# STM32F437 register map
File version: 1.3
CPU: CM4 r0p1, little endian, MPU, FPU, 4 interrupt priority bits
Registers are 32-bit, read-write, reset 0x0 unless marked. A register's access mark holds for its fields unless they carry their own. Offsets are from the block's base; [hi:lo] are bit positions; {n}, {i} and the like mark numbered series; 'fields as' and 'values as' point back to an identical list.

## Ethernet_PTP — Ethernet: Precision time protocol
Base 0x40028700
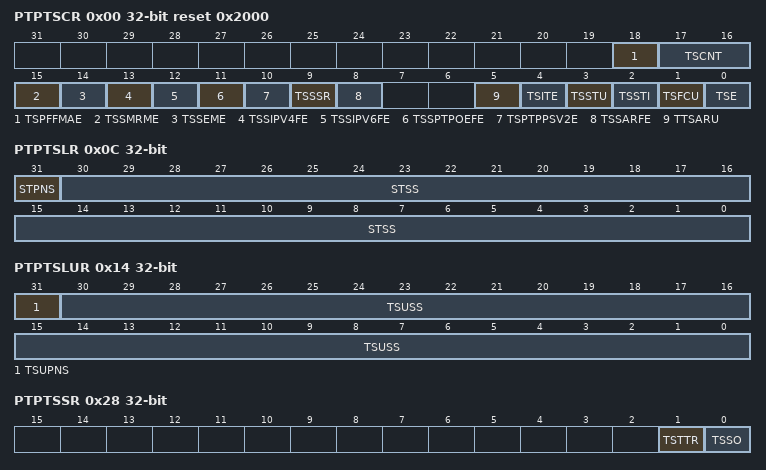
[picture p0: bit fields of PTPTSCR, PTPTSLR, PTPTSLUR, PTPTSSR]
0x00 PTPTSCR reset 0x2000 — Ethernet PTP time stamp control register
  [18] TSPFFMAE, [17:16] TSCNT, [15] TSSMRME, [14] TSSEME, [13] TSSIPV4FE, [12] TSSIPV6FE, [11] TSSPTPOEFE, [10] TSPTPPSV2E, [9] TSSSR, [8] TSSARFE, [5] TTSARU, [4] TSITE, [3] TSSTU, [2] TSSTI, [1] TSFCU, [0] TSE
0x04 PTPSSIR — Ethernet PTP subsecond increment register
  [7:0] STSSI
0x08 PTPTSHR ro — Ethernet PTP time stamp high register
  [31:0] STS
0x0C PTPTSLR ro — Ethernet PTP time stamp low register
  [31] STPNS, [30:0] STSS
0x10 PTPTSHUR — Ethernet PTP time stamp high update register
  [31:0] TSUS
0x14 PTPTSLUR — Ethernet PTP time stamp low update register
  [31] TSUPNS, [30:0] TSUSS
0x18 PTPTSAR — Ethernet PTP time stamp addend register
  [31:0] TSA
0x1C PTPTTHR — Ethernet PTP target time high register
  [31:0] TTSH — 0
0x20 PTPTTLR — Ethernet PTP target time low register
  [31:0] TTSL
0x28 PTPTSSR ro — Ethernet PTP time stamp status register
  [1] TSTTR, [0] TSSO
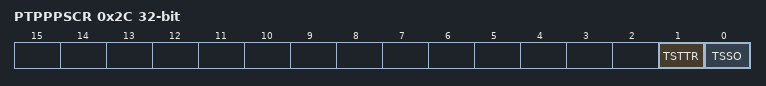
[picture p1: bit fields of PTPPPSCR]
0x2C PTPPPSCR ro — Ethernet PTP PPS control register
  [1] TSTTR, [0] TSSO

## Ethernet_DMA — Ethernet: DMA controller operation
Base 0x40029000
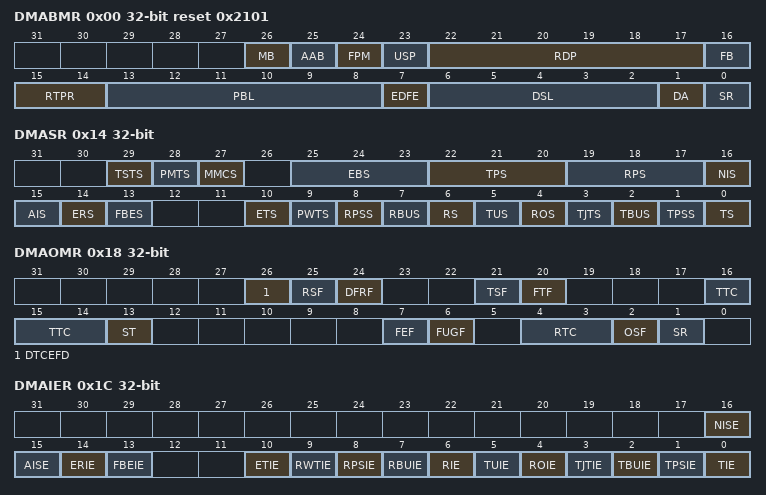
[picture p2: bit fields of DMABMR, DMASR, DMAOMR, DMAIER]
0x00 DMABMR reset 0x2101 — Ethernet DMA bus mode register
  [26] MB, [25] AAB, [24] FPM, [23] USP, [22:17] RDP, [16] FB, [15:14] RTPR, [13:8] PBL, [7] EDFE, [6:2] DSL, [1] DA, [0] SR
0x04 DMATPDR — Ethernet DMA transmit poll demand register
  [31:0] TPD
0x08 DMARPDR — EHERNET DMA receive poll demand register
  [31:0] RPD
0x0C DMARDLAR — Ethernet DMA receive descriptor list address register
  [31:0] SRL
0x10 DMATDLAR — Ethernet DMA transmit descriptor list address register
  [31:0] STL
0x14 DMASR access per field — Ethernet DMA status register
  [29] TSTS ro
  [28] PMTS ro
  [27] MMCS ro
  [25:23] EBS ro
  [22:20] TPS ro
  [19:17] RPS ro
  [16] NIS rw
  [15] AIS rw
  [14] ERS rw
  [13] FBES rw
  [10] ETS rw
  [9] PWTS rw
  [8] RPSS rw
  [7] RBUS rw
  [6] RS rw
  [5] TUS rw
  [4] ROS rw
  [3] TJTS rw
  [2] TBUS rw — TPSS
  [1] TPSS rw
  [0] TS rw
0x18 DMAOMR — Ethernet DMA operation mode register
  [26] DTCEFD, [25] RSF, [24] DFRF, [21] TSF, [20] FTF, [16:14] TTC, [13] ST, [7] FEF, [6] FUGF, [4:3] RTC, [2] OSF, [1] SR
0x1C DMAIER — Ethernet DMA interrupt enable register
  [16] NISE, [15] AISE, [14] ERIE, [13] FBEIE, [10] ETIE, [9] RWTIE, [8] RPSIE, [7] RBUIE, [6] RIE, [5] TUIE, [4] ROIE, [3] TJTIE, [2] TBUIE, [1] TPSIE, [0] TIE
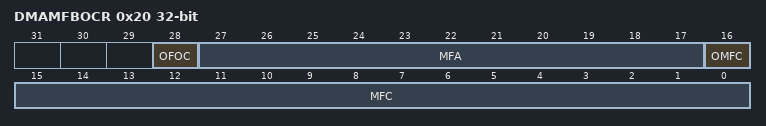
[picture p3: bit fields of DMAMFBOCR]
0x20 DMAMFBOCR — Ethernet DMA missed frame and buffer overflow counter register
  [28] OFOC, [27:17] MFA, [16] OMFC, [15:0] MFC
0x24 DMARSWTR — Ethernet DMA receive status watchdog timer register
  [7:0] RSWTC
0x48 DMACHTDR ro — Ethernet DMA current host transmit descriptor register
  [31:0] HTDAP
0x4C DMACHRDR ro — Ethernet DMA current host receive descriptor register
  [31:0] HRDAP
0x50 DMACHTBAR ro — Ethernet DMA current host transmit buffer address register
  [31:0] HTBAP
0x54 DMACHRBAR ro — Ethernet DMA current host receive buffer address register
  [31:0] HRBAP

## CRC — Cryptographic processor
Base 0x40023000
0x00 DR reset 0xFFFFFFFF — Data register
  [31:0] DR — Data Register
0x04 IDR — Independent Data register
  [7:0] IDR
0x08 CR wo — Control register
  [0] CR — Control regidter

## OTG_FS_HOST — USB on the go full speed
Base 0x50000400
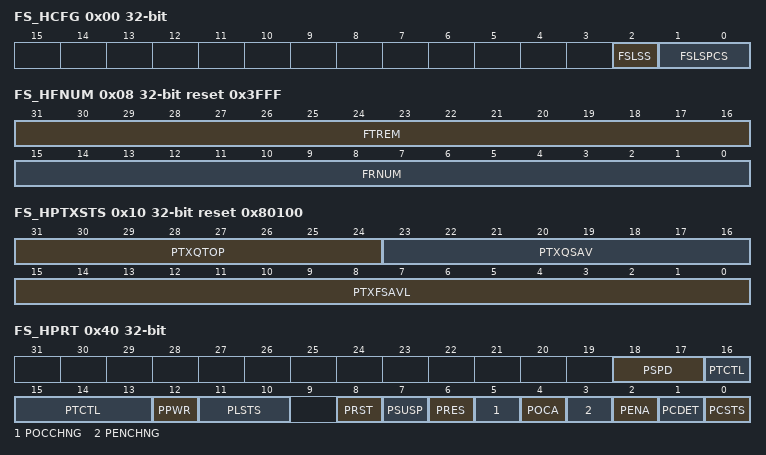
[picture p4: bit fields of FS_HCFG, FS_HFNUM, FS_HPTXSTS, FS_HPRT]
0x00 FS_HCFG access per field — OTG_FS host configuration register (OTG_FS_HCFG)
  [2] FSLSS ro — FS- and LS-only support
  [1:0] FSLSPCS rw — FS/LS PHY clock select
0x04 HFIR reset 0xEA60 — OTG_FS Host frame interval register
  [15:0] FRIVL — Frame interval
0x08 FS_HFNUM ro reset 0x3FFF — OTG_FS host frame number/frame time remaining register (OTG_FS_HFNUM)
  [31:16] FTREM — Frame time remaining
  [15:0] FRNUM — Frame number
0x10 FS_HPTXSTS access per field reset 0x80100 — OTG_FS_Host periodic transmit FIFO/queue status register (OTG_FS_HPTXSTS)
  [31:24] PTXQTOP ro — Top of the periodic transmit request queue
  [23:16] PTXQSAV ro — Periodic transmit request queue space available
  [15:0] PTXFSAVL rw — Periodic transmit data FIFO space available
0x14 HAINT ro — OTG_FS Host all channels interrupt register
  [15:0] HAINT — Channel interrupts
0x18 HAINTMSK — OTG_FS host all channels interrupt mask register
  [15:0] HAINTM — Channel interrupt mask
0x40 FS_HPRT access per field — OTG_FS host port control and status register (OTG_FS_HPRT)
  [18:17] PSPD ro — Port speed
  [16:13] PTCTL rw — Port test control
  [12] PPWR rw — Port power
  [11:10] PLSTS ro — Port line status
  [8] PRST rw — Port reset
  [7] PSUSP rw — Port suspend
  [6] PRES rw — Port resume
  [5] POCCHNG rw — Port overcurrent change
  [4] POCA ro — Port overcurrent active
  [3] PENCHNG rw — Port enable/disable change
  [2] PENA rw — Port enable
  [1] PCDET rw — Port connect detected
  [0] PCSTS ro — Port connect status
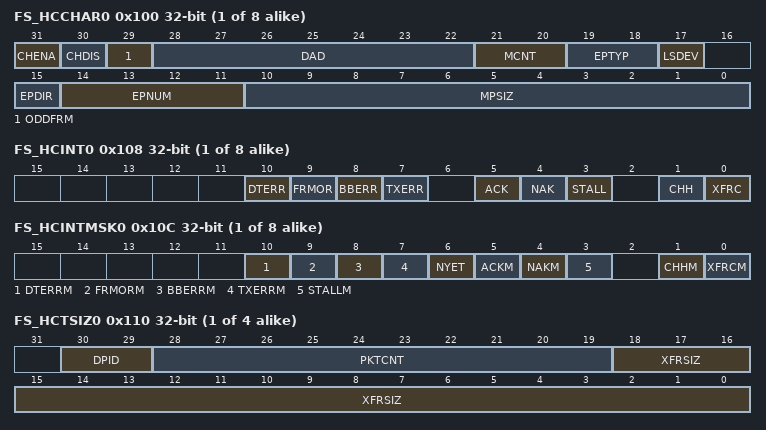
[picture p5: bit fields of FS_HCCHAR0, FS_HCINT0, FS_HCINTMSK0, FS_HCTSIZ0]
{0x100+0x20*i} FS_HCCHAR{i} (i=0..7) — OTG_FS host channel-{i} characteristics register (OTG_FS_HCCHAR{i})
  [31] CHENA — Channel enable
  [30] CHDIS — Channel disable
  [29] ODDFRM — Odd frame
  [28:22] DAD — Device address
  [21:20] MCNT — Multicount
  [19:18] EPTYP — Endpoint type
  [17] LSDEV — Low-speed device
  [15] EPDIR — Endpoint direction
  [14:11] EPNUM — Endpoint number
  [10:0] MPSIZ — Maximum packet size
{0x108+0x20*i} FS_HCINT{i} (i=0..7) — OTG_FS host channel-{i} interrupt register (OTG_FS_HCINT{i})
  [10] DTERR — Data toggle error
  [9] FRMOR — Frame overrun
  [8] BBERR — Babble error
  [7] TXERR — Transaction error
  [5] ACK — ACK response received/transmitted interrupt
  [4] NAK — NAK response received interrupt
  [3] STALL — STALL response received interrupt
  [1] CHH — Channel halted
  [0] XFRC — Transfer completed
{0x10C+0x20*i} FS_HCINTMSK{i} (i=0..7) — OTG_FS host channel-{i} mask register (OTG_FS_HCINTMSK{i})
  [10] DTERRM — Data toggle error mask
  [9] FRMORM — Frame overrun mask
  [8] BBERRM — Babble error mask
  [7] TXERRM — Transaction error mask
  [6] NYET — response received interrupt mask
  [5] ACKM — ACK response received/transmitted interrupt mask
  [4] NAKM — NAK response received interrupt mask
  [3] STALLM — STALL response received interrupt mask
  [1] CHHM — Channel halted mask
  [0] XFRCM — Transfer completed mask
{0x110+0x20*i} FS_HCTSIZ{i} (i=0..3) — OTG_FS host channel-{i} transfer size register
  [30:29] DPID — Data PID
  [28:19] PKTCNT — Packet count
  [18:0] XFRSIZ — Transfer size
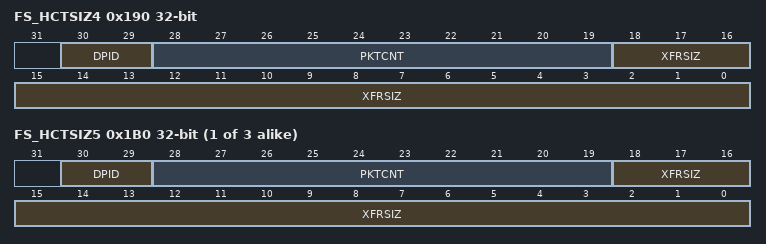
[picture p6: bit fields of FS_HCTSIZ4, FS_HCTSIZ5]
0x190 FS_HCTSIZ4 — OTG_FS host channel-x transfer size register
  fields as FS_HCTSIZ0
{0x110+0x20*i} FS_HCTSIZ{i} (i=5..7) — OTG_FS host channel-{i} transfer size register
  fields as FS_HCTSIZ0

## Notices in the file
Copyright (c) 2024 STMicroelectronics.
SPDX-License-Identifier: Apache-2.0
Licensed under the Apache License, Version 2.0 (the "License");
you may not use this file except in compliance with the License.
You may obtain a copy of the License at
http://www.apache.org/licenses/LICENSE-2.0
Unless required by applicable law or agreed to in writing, software
distributed under the License is distributed on an "AS IS" BASIS,
WITHOUT WARRANTIES OR CONDITIONS OF ANY KIND, either express or implied.
See the License for the specific language governing permissions and
limitations under the License.
